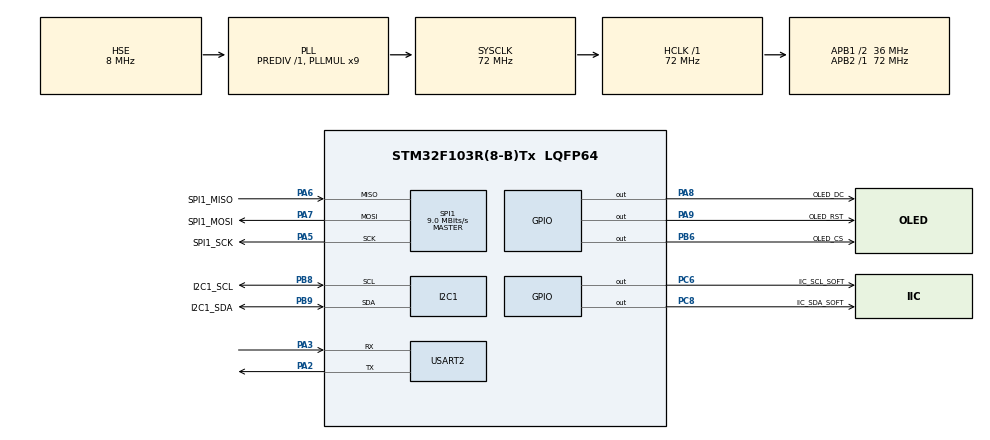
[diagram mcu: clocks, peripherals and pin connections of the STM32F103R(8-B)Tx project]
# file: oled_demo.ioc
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Mcu.Family=STM32F1
RCC.PLLSourceVirtual=RCC_PLLSOURCE_HSE
PA6.Mode=Full_Duplex_Master
PA7.Mode=Full_Duplex_Master
PD1-OSC_OUT.Mode=HSE-External-Oscillator
PB9.GPIO_Label=I2C1_SDA
SPI1.VirtualType=VM_MASTER
PA9.GPIO_Label=OLED_RST
PC8.Signal=GPIO_Output
PC6.Signal=GPIO_Output
PC6.GPIO_Label=IIC_SCL_SOFT
PA6.GPIO_Label=SPI1_MISO
PB6.GPIO_Label=OLED_CS
SPI1.CLKPhase=SPI_PHASE_2EDGE
PD0-OSC_IN.Signal=RCC_OSC_IN
RCC.APB1CLKDivider=RCC_HCLK_DIV2
RCC.SYSCLKSource=RCC_SYSCLKSOURCE_PLLCLK
ProjectManager.StackSize=0x400
PD1-OSC_OUT.Signal=RCC_OSC_OUT
PC8.GPIO_Label=IIC_SDA_SOFT
PA13.Signal=SYS_JTMS-SWDIO
PA3.Mode=Asynchronous
PB8.GPIO_Label=I2C1_SCL
PA8.GPIO_Label=OLED_DC
SPI1.CLKPolarity=SPI_POLARITY_HIGH
ProjectManager.TargetToolchain=MDK-ARM V5.27
SPI1.Direction=SPI_DIRECTION_2LINES
RCC.HCLKFreq_Value=72000000
PB9.Mode=I2C
RCC.APB2TimFreq_Value=72000000
PA9.Signal=GPIO_Output
PB6.Signal=GPIO_Output
SPI1.CalculateBaudRate=9.0 MBits/s
RCC.USBFreq_Value=72000000
RCC.AHBFreq_Value=72000000
PD0-OSC_IN.Mode=HSE-External-Oscillator
PA5.Signal=SPI1_SCK
board=custom
RCC.PLLMUL=RCC_PLL_MUL9
PB9.GPIO_Mode=GPIO_MODE_AF_OD
RCC.APB2Freq_Value=72000000
SPI1.Mode=SPI_MODE_MASTER
PA14.Mode=Serial_Wire
PA8.Signal=GPIO_Output
PA8.GPIO_ModeDefaultOutputPP=GPIO_MODE_OUTPUT_PP
PA13.Mode=Serial_Wire
Mcu.Name=STM32F103R(8-B)Tx
PA2.Signal=USART2_TX
PC8.GPIO_PuPd=GPIO_PULLUP
RCC.SYSCLKFreq_VALUE=72000000
Mcu.Package=LQFP64
PB9.Signal=I2C1_SDA
PA6.Signal=SPI1_MISO
PA7.GPIO_Label=SPI1_MOSI
PA5.GPIO_Label=SPI1_SCK
USART2.VirtualMode=VM_ASYNC
PA14.Signal=SYS_JTCK-SWCLK
ProjectManager.HeapSize=0x2000
PC6.GPIO_PuPd=GPIO_PULLUP
PC8.GPIO_Speed=GPIO_SPEED_FREQ_LOW
NVIC.PriorityGroup=NVIC_PRIORITYGROUP_4
PB8.Mode=I2C
RCC.APB1TimFreq_Value=72000000
PA2.Mode=Asynchronous
PB8.Signal=I2C1_SCL
RCC.APB1Freq_Value=36000000
SPI1.BaudRatePrescaler=SPI_BAUDRATEPRESCALER_8
PC6.GPIO_Speed=GPIO_SPEED_FREQ_LOW
PA3.Signal=USART2_RX
PA5.Mode=Full_Duplex_Master
PA7.Signal=SPI1_MOSI

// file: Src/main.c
/* USER CODE BEGIN Header */
/**
  ******************************************************************************
  * @file           : main.c
  * @brief          : Main program body
  ******************************************************************************
  * @attention
  *
  * <h2><center>&copy; Copyright (c) 2020 STMicroelectronics.
  * All rights reserved.</center></h2>
  *
  * This software component is licensed by ST under BSD 3-Clause license,
  * the "License"; You may not use this file except in compliance with the
  * License. You may obtain a copy of the License at:
  *                        opensource.org/licenses/BSD-3-Clause
  *
  ******************************************************************************
  */
/* USER CODE END Header */

#include "main.h"
#include "i2c.h"
#include "spi.h"
#include "usart.h"
#include "gpio.h"

/* USER CODE BEGIN Includes */
#include "test.h"
/* USER CODE END Includes */

void SystemClock_Config(void);

int main(void)
{

  /* MCU Configuration--------------------------------------------------------*/

  /* Reset of all peripherals, Initializes the Flash interface and the Systick. */
  HAL_Init();

  /* Configure the system clock */
  SystemClock_Config();

  /* Initialize all configured peripherals */
  MX_GPIO_Init();
  MX_SPI1_Init();
  MX_USART2_UART_Init();
  MX_I2C1_Init();
  /* USER CODE BEGIN 2 */

//	OLED_0in91_test();	//	Only IIC !!!

//	OLED_0in95_rgb_test();	//	Only SPI !!!

//	OLED_0in96_test();		//	IIC must USE_IIC_SOFT

//	OLED_1in3_test();		//	IIC must USE_IIC_SOFT

	//OLED_1in3_c_test();

//	OLED_1in5_test();

		OLED_1in51_test();

//	OLED_1in5_rgb_test();	//	Only SPI !!!

  /* USER CODE END 2 */

  /* Infinite loop */
  while (1)
  {

  }
}

void SystemClock_Config(void)
{
  RCC_OscInitTypeDef RCC_OscInitStruct = {0};
  RCC_ClkInitTypeDef RCC_ClkInitStruct = {0};

  /** Initializes the CPU, AHB and APB busses clocks
  */
  RCC_OscInitStruct.OscillatorType = RCC_OSCILLATORTYPE_HSE;
  RCC_OscInitStruct.HSEState = RCC_HSE_ON;
  RCC_OscInitStruct.HSEPredivValue = RCC_HSE_PREDIV_DIV1;
  RCC_OscInitStruct.HSIState = RCC_HSI_ON;
  RCC_OscInitStruct.PLL.PLLState = RCC_PLL_ON;
  RCC_OscInitStruct.PLL.PLLSource = RCC_PLLSOURCE_HSE;
  RCC_OscInitStruct.PLL.PLLMUL = RCC_PLL_MUL9;
  if (HAL_RCC_OscConfig(&RCC_OscInitStruct) != HAL_OK)
  {
    Error_Handler();
  }
  /** Initializes the CPU, AHB and APB busses clocks
  */
  RCC_ClkInitStruct.ClockType = RCC_CLOCKTYPE_HCLK|RCC_CLOCKTYPE_SYSCLK
                              |RCC_CLOCKTYPE_PCLK1|RCC_CLOCKTYPE_PCLK2;
  RCC_ClkInitStruct.SYSCLKSource = RCC_SYSCLKSOURCE_PLLCLK;
  RCC_ClkInitStruct.AHBCLKDivider = RCC_SYSCLK_DIV1;
  RCC_ClkInitStruct.APB1CLKDivider = RCC_HCLK_DIV2;
  RCC_ClkInitStruct.APB2CLKDivider = RCC_HCLK_DIV1;

  if (HAL_RCC_ClockConfig(&RCC_ClkInitStruct, FLASH_LATENCY_2) != HAL_OK)
  {
    Error_Handler();
  }
}

void Error_Handler(void)
{
  while(1)
  {
  }
}

/************************ (C) COPYRIGHT STMicroelectronics *****END OF FILE****/
